# alb32r003x register map
Vendor: ALB; Series: ALB RT SoC
CPU: ALB XF, little endian
Registers are 32-bit, access not given, reset 0x0 unless marked. A register's access mark holds for its fields unless they carry their own. Offsets are from the block's base; [hi:lo] are bit positions; {n}, {i} and the like mark numbered series.

## DMA1_CTL_STA
Base 0x230022C0
Same registers: DMA2_CTL_STA 0x230032C0
0x00 RawTfr_L
  [7:0] RAW — Raw Status for IntTfr Interrupt
0x04 RawTfr_H
0x08 RawBlock_L
  [7:0] RAW — Raw Status for IntBlock Interrupt
0x0C RawBlock_H
0x10 RawSrcTran_L
  [7:0] RAW — Raw Status for IntSrcTran Interrupt
0x14 RawSrcTran_H
0x18 RawDstTran_L
  [7:0] RAW — Raw Status for IntDstTran Interrupt
0x1C RawDstTran_H
0x20 RawErr_L
  [7:0] RAW — Raw Status for IntErr Interrupt
0x24 RawErr_H
0x28 StatusTfr_L
  [7:0] STATUS — Status for IntTfr Interrupt
0x2C StatusTfr_H
0x30 StatusBlock_L
  [7:0] STATUS — Status for IntBlock Interrupt
0x34 StatusBlock_H
0x38 StatusSrcTran_L
  [7:0] STATUS — Status for IntSrcTran Interrupt
0x3C StatusSrcTran_H
0x40 StatusDstTran_L
  [7:0] STATUS — Status for IntDstTran Interrupt
0x44 StatusDstTran_H
0x48 StatusErr_L
  [7:0] STATUS — Status for IntErr Interrupt
0x4C StatusErr_H
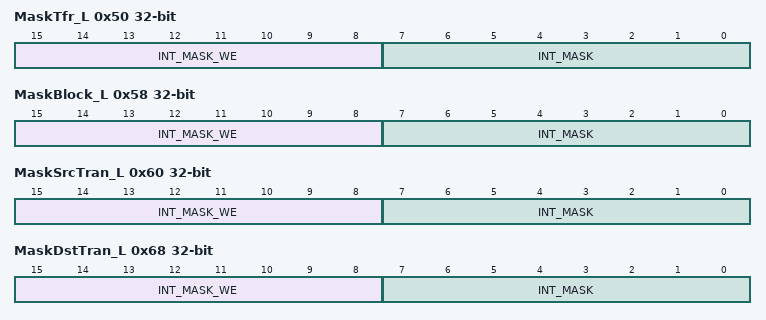
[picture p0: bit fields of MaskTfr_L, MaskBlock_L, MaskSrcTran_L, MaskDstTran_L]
0x50 MaskTfr_L
  [15:8] INT_MASK_WE — Interrupt Mask Write Enable
  [7:0] INT_MASK — Mask for IntTfr Interrupt
0x54 MaskTfr_H
0x58 MaskBlock_L
  [15:8] INT_MASK_WE — Interrupt Mask Write Enable
  [7:0] INT_MASK — Mask for IntBlock Interrupt
0x5C MaskBlock_H
0x60 MaskSrcTran_L
  [15:8] INT_MASK_WE — Interrupt Mask Write Enable
  [7:0] INT_MASK — Mask for IntSrcTran Interrupt
0x64 MaskSrcTran_H
0x68 MaskDstTran_L
  [15:8] INT_MASK_WE — Interrupt Mask Write Enable
  [7:0] INT_MASK — Mask for IntDstTran Interrupt
0x6C MaskDstTran_H
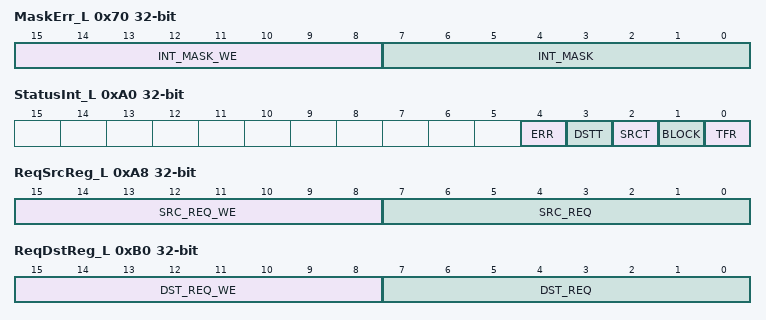
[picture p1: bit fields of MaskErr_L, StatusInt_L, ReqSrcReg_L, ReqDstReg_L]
0x70 MaskErr_L
  [15:8] INT_MASK_WE — Interrupt Mask Write Enable
  [7:0] INT_MASK — Mask for IntErr Interrupt
0x74 MaskErr_H
0x78 ClearTfr_L
  [7:0] CLEAR — Clear for IntTfr Interrupt
0x7C ClearTfr_H
0x80 ClearBlock_L
  [7:0] CLEAR — Clear for IntBlock Interrupt
0x84 ClearBlock_H
0x88 ClearSrcTran_L
  [7:0] CLEAR — Clear for IntSrcTran Interrupt
0x8C ClearSrcTran_H
0x90 ClearDstTran_L
  [7:0] CLEAR — Clear for IntDstTran Interrupt
0x94 ClearDstTran_H
0x98 ClearErr_L
  [7:0] CLEAR — Clear for IntErr Interrupt
0x9C ClearErr_H
0xA0 StatusInt_L
  [4] ERR — OR of the contents of StatusErr
  [3] DSTT — OR of the contents of StatusDstTran
  [2] SRCT — OR of the contents of StatusSrcTran
  [1] BLOCK — OR of the contents of StatusBlock register
  [0] TFR — OR of the contents of StatusTfr register
0xA4 StatusInt_H
0xA8 ReqSrcReg_L
  [15:8] SRC_REQ_WE — Source Software Transaction Request write enable
  [7:0] SRC_REQ — Source Software Transaction Request
0xAC ReqSrcReg_H
0xB0 ReqDstReg_L
  [15:8] DST_REQ_WE — Destination Software Transaction Request write enable
  [7:0] DST_REQ — Destination Software Transaction Request
0xB4 ReqDstReg_H
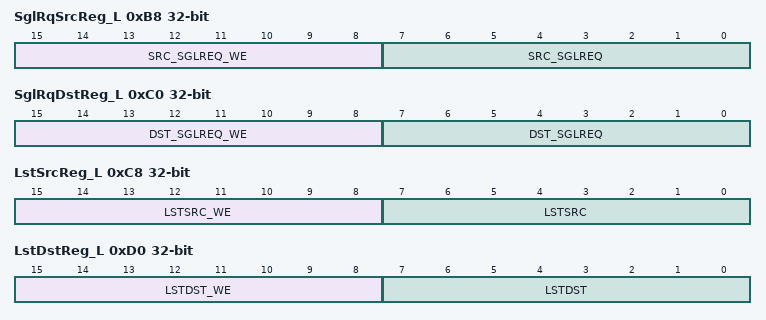
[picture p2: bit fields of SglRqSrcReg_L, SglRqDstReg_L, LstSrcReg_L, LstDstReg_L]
0xB8 SglRqSrcReg_L
  [15:8] SRC_SGLREQ_WE — Source Single Transaction Request write enable
  [7:0] SRC_SGLREQ — Source Single Transaction Request
0xBC SglRqSrcReg_H
0xC0 SglRqDstReg_L
  [15:8] DST_SGLREQ_WE — Destination Single Transaction Request write enable
  [7:0] DST_SGLREQ — Destination Single Transaction Request
0xC4 SglRqDstReg_H
0xC8 LstSrcReg_L
  [15:8] LSTSRC_WE — Source Last Transaction Request write enable
  [7:0] LSTSRC — Source Last Transaction Request register
0xCC LstSrcReg_H
0xD0 LstDstReg_L
  [15:8] LSTDST_WE — Source Last Transaction Request write enable
  [7:0] LSTDST — Destination Last Transaction Request
0xD4 LstDstReg_H
0xD8 DmaCfgReg_L
  [0] DMA_EN — DW_ahb_dmac Enable bit.
0xDC DmaCfgReg_H
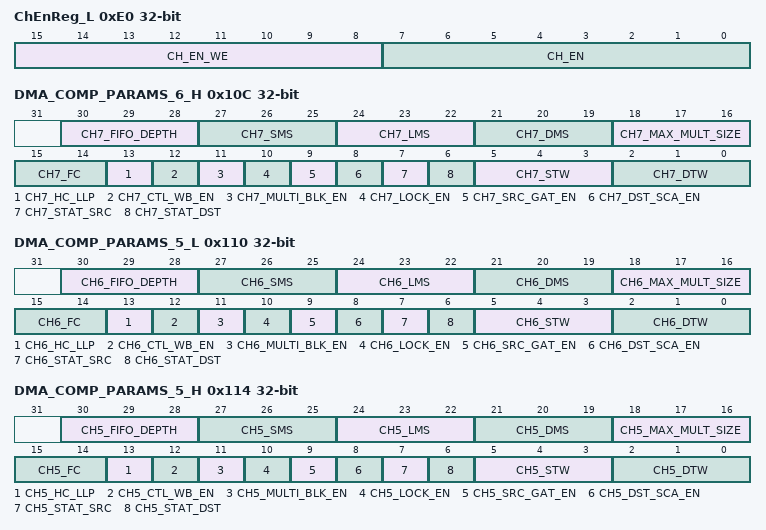
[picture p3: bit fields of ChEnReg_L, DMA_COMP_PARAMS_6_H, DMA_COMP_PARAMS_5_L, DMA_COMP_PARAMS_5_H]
0xE0 ChEnReg_L
  [15:8] CH_EN_WE — Channel enable register
  [7:0] CH_EN — Channel Enable. The ChEnReg.CH_EN bit is automatically
0xE4 ChEnReg_H
0xE8 DmaIdReg_L
  [31:0] DMA_ID — Hardcoded DW_ahb_dmac peripheral ID.
0xEC DmaIdReg_H
0xF0 DmaTestReg_L
  [0] TEST_SLV_IF — DMA Test register
0xF4 DmaTestReg_H
0xF8 DmaLpTimeoutReg_L
  [31:0] DMA_LP_TIMEOUT — This field holds timeout value of low power counter register.
0xFC DmaLpTimeoutReg_H
0x108 DMA_COMP_PARAMS_6_L
0x10C DMA_COMP_PARAMS_6_H
  [30:28] CH7_FIFO_DEPTH — Channel 7 FIFO depth
  [27:25] CH7_SMS — Channel 7 Source Master
  [24:22] CH7_LMS — Channel 7 LLP Master
  [21:19] CH7_DMS — Channel 7 Destination Master
  [18:16] CH7_MAX_MULT_SIZE — Channel 7 Maximum MULT Size
  [15:14] CH7_FC — Channel 7 Flow Controller
  [13] CH7_HC_LLP — Channel 7 Hardcode LLP
  [12] CH7_CTL_WB_EN — Channel 7 Control Writeback Enable
  [11] CH7_MULTI_BLK_EN — Channel 7 MultiBlock Enable
  [10] CH7_LOCK_EN — Channel 7 locking Enable
  [9] CH7_SRC_GAT_EN — Channel 7 Source gather Enable
  [8] CH7_DST_SCA_EN — Channel 7 Destination scatter Enable
  [7] CH7_STAT_SRC — Channel 7 Status Source
  [6] CH7_STAT_DST — Channel 7 Status Destination
  [5:3] CH7_STW — Channel 7 Source Transfer Width
  [2:0] CH7_DTW — Channel 7 Destination Transfer Width
0x110 DMA_COMP_PARAMS_5_L
  [30:28] CH6_FIFO_DEPTH — Channel 6 FIFO depth
  [27:25] CH6_SMS — Channel 6 Source Master
  [24:22] CH6_LMS — Channel 6 LLP Master
  [21:19] CH6_DMS — Channel 6 Destination Master
  [18:16] CH6_MAX_MULT_SIZE — Channel 6 Maximum MULT Size
  [15:14] CH6_FC — Channel 6 Flow Controller
  [13] CH6_HC_LLP — Channel 6 Hardcode LLP
  [12] CH6_CTL_WB_EN — Channel 6 Control Writeback Enable
  [11] CH6_MULTI_BLK_EN — Channel 6 MultiBlock Enable
  [10] CH6_LOCK_EN — Channel 6 locking Enable
  [9] CH6_SRC_GAT_EN — Channel 6 Source gather Enable
  [8] CH6_DST_SCA_EN — Channel 6 Destination scatter Enable
  [7] CH6_STAT_SRC — Channel 6 Status Source
  [6] CH6_STAT_DST — Channel 6 Status Destination
  [5:3] CH6_STW — Channel 6 Source Transfer Width
  [2:0] CH6_DTW — Channel 6 Destination Transfer Width
0x114 DMA_COMP_PARAMS_5_H
  [30:28] CH5_FIFO_DEPTH — Channel 5 FIFO depth
  [27:25] CH5_SMS — Channel 5 Source Master
  [24:22] CH5_LMS — Channel 5 LLP Master
  [21:19] CH5_DMS — Channel 5 Destination Master
  [18:16] CH5_MAX_MULT_SIZE — Channel 5 Maximum MULT Size
  [15:14] CH5_FC — Channel 5 Flow Controller
  [13] CH5_HC_LLP — Channel 5 Hardcode LLP
  [12] CH5_CTL_WB_EN — Channel 5 Control Writeback Enable
  [11] CH5_MULTI_BLK_EN — Channel 5 MultiBlock Enable
  [10] CH5_LOCK_EN — Channel 5 locking Enable
  [9] CH5_SRC_GAT_EN — Channel 5 Source gather Enable
  [8] CH5_DST_SCA_EN — Channel 5 Destination scatter Enable
  [7] CH5_STAT_SRC — Channel 5 Status Source
  [6] CH5_STAT_DST — Channel 5 Status Destination
  [5:3] CH5_STW — Channel 5 Source Transfer Width
  [2:0] CH5_DTW — Channel 5 Destination Transfer Width
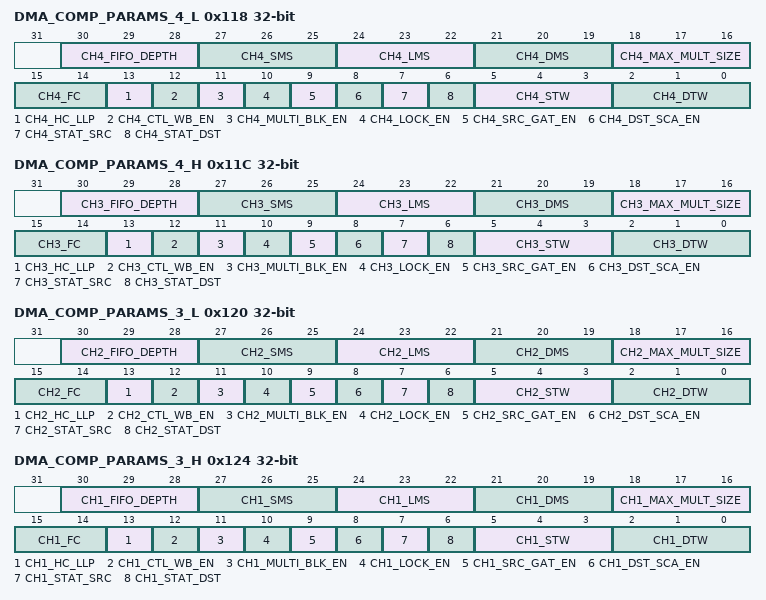
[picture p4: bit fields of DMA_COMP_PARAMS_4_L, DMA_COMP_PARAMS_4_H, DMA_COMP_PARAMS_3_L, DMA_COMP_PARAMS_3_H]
0x118 DMA_COMP_PARAMS_4_L
  [30:28] CH4_FIFO_DEPTH — Channel 4 FIFO depth
  [27:25] CH4_SMS — Channel 4 Source Master
  [24:22] CH4_LMS — Channel 4 LLP Master
  [21:19] CH4_DMS — Channel 4 Destination Master
  [18:16] CH4_MAX_MULT_SIZE — Channel 4 Maximum MULT Size
  [15:14] CH4_FC — Channel 4 Flow Controller
  [13] CH4_HC_LLP — Channel 4 Hardcode LLP
  [12] CH4_CTL_WB_EN — Channel 4 Control Writeback Enable
  [11] CH4_MULTI_BLK_EN — Channel 4 MultiBlock Enable
  [10] CH4_LOCK_EN — Channel 4 locking Enable
  [9] CH4_SRC_GAT_EN — Channel 4 Source gather Enable
  [8] CH4_DST_SCA_EN — Channel 4 Destination scatter Enable
  [7] CH4_STAT_SRC — Channel 4 Status Source
  [6] CH4_STAT_DST — Channel 4 Status Destination
  [5:3] CH4_STW — Channel 4 Source Transfer Width
  [2:0] CH4_DTW — Channel 4 Destination Transfer Width
0x11C DMA_COMP_PARAMS_4_H
  [30:28] CH3_FIFO_DEPTH — Channel 3 FIFO depth
  [27:25] CH3_SMS — Channel 3 Source Master
  [24:22] CH3_LMS — Channel 3 LLP Master
  [21:19] CH3_DMS — Channel 3 Destination Master
  [18:16] CH3_MAX_MULT_SIZE — Channel 3 Maximum MULT Size
  [15:14] CH3_FC — Channel 3 Flow Controller
  [13] CH3_HC_LLP — Channel 3 Hardcode LLP
  [12] CH3_CTL_WB_EN — Channel 3 Control Writeback Enable
  [11] CH3_MULTI_BLK_EN — Channel 3 MultiBlock Enable
  [10] CH3_LOCK_EN — Channel 3 locking Enable
  [9] CH3_SRC_GAT_EN — Channel 3 Source gather Enable
  [8] CH3_DST_SCA_EN — Channel 3 Destination scatter Enable
  [7] CH3_STAT_SRC — Channel 3 Status Source
  [6] CH3_STAT_DST — Channel 3 Status Destination
  [5:3] CH3_STW — Channel 3 Source Transfer Width
  [2:0] CH3_DTW — Channel 3 Destination Transfer Width
0x120 DMA_COMP_PARAMS_3_L
  [30:28] CH2_FIFO_DEPTH — Channel 2 FIFO depth
  [27:25] CH2_SMS — Channel 2 Source Master
  [24:22] CH2_LMS — Channel 2 LLP Master
  [21:19] CH2_DMS — Channel 2 Destination Master
  [18:16] CH2_MAX_MULT_SIZE — Channel 2 Maximum MULT Size
  [15:14] CH2_FC — Channel 2 Flow Controller
  [13] CH2_HC_LLP — Channel 2 Hardcode LLP
  [12] CH2_CTL_WB_EN — Channel 2 Control Writeback Enable
  [11] CH2_MULTI_BLK_EN — Channel 2 MultiBlock Enable
  [10] CH2_LOCK_EN — Channel 2 locking Enable
  [9] CH2_SRC_GAT_EN — Channel 2 Source gather Enable
  [8] CH2_DST_SCA_EN — Channel 2 Destination scatter Enable
  [7] CH2_STAT_SRC — Channel 2 Status Source
  [6] CH2_STAT_DST — Channel 2 Status Destination
  [5:3] CH2_STW — Channel 2 Source Transfer Width
  [2:0] CH2_DTW — Channel 2 Destination Transfer Width
0x124 DMA_COMP_PARAMS_3_H
  [30:28] CH1_FIFO_DEPTH — Channel 1 FIFO depth
  [27:25] CH1_SMS — Channel 1 Source Master
  [24:22] CH1_LMS — Channel 1 LLP Master
  [21:19] CH1_DMS — Channel 1 Destination Master
  [18:16] CH1_MAX_MULT_SIZE — Channel 1 Maximum MULT Size
  [15:14] CH1_FC — Channel 1 Flow Controller
  [13] CH1_HC_LLP — Channel 1 Hardcode LLP
  [12] CH1_CTL_WB_EN — Channel 1 Control Writeback Enable
  [11] CH1_MULTI_BLK_EN — Channel 1 MultiBlock Enable
  [10] CH1_LOCK_EN — Channel 1 locking Enable
  [9] CH1_SRC_GAT_EN — Channel 1 Source gather Enable
  [8] CH1_DST_SCA_EN — Channel 1 Destination scatter Enable
  [7] CH1_STAT_SRC — Channel 1 Status Source
  [6] CH1_STAT_DST — Channel 1 Status Destination
  [5:3] CH1_STW — Channel 1 Source Transfer Width
  [2:0] CH1_DTW — Channel 1 Destination Transfer Width
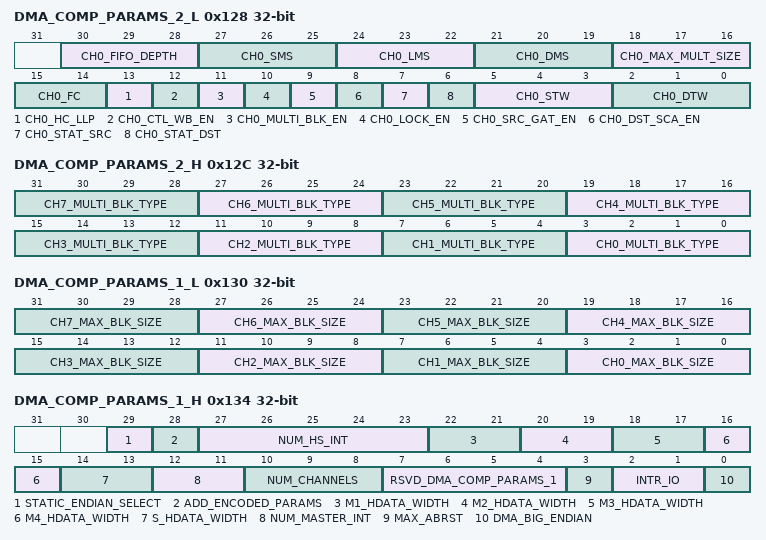
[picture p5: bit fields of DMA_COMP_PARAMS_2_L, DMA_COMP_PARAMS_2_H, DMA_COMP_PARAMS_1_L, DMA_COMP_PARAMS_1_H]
0x128 DMA_COMP_PARAMS_2_L
  [30:28] CH0_FIFO_DEPTH — Channel 0 FIFO depth
  [27:25] CH0_SMS — Channel 0 Source Master
  [24:22] CH0_LMS — Channel 0 LLP Master
  [21:19] CH0_DMS — Channel 0 Destination Master
  [18:16] CH0_MAX_MULT_SIZE — Channel 0 Maximum MULT Size
  [15:14] CH0_FC — Channel 0 Flow Controller
  [13] CH0_HC_LLP — Channel 0 Hardcode LLP
  [12] CH0_CTL_WB_EN — Channel 0 Control Writeback Enable
  [11] CH0_MULTI_BLK_EN — Channel 0 MultiBlock Enable
  [10] CH0_LOCK_EN — Channel 0 locking Enable
  [9] CH0_SRC_GAT_EN — Channel 0 Source gather Enable
  [8] CH0_DST_SCA_EN — Channel 0 Destination scatter Enable
  [7] CH0_STAT_SRC — Channel 0 Status Source
  [6] CH0_STAT_DST — Channel 0 Status Destination
  [5:3] CH0_STW — Channel 0 Source Transfer Width
  [2:0] CH0_DTW — Channel 0 Destination Transfer Width
0x12C DMA_COMP_PARAMS_2_H
  [4n+3:4n] CH{n}_MULTI_BLK_TYPE (n=0..7) — Channel {n} MultiBlock Type
0x130 DMA_COMP_PARAMS_1_L
  [4n+3:4n] CH{n}_MAX_BLK_SIZE (n=0..7) — Channel {n} Maximum Block Size
0x134 DMA_COMP_PARAMS_1_H
  [29] STATIC_ENDIAN_SELECT
  [28] ADD_ENCODED_PARAMS — Add Encoded Parameter
  [27:23] NUM_HS_INT — Number of handshaking interfaces
  [24-2n:23-2n] M{n}_HDATA_WIDTH (n=1..4) — Master{n} Interface Data Bus Width
  [14:13] S_HDATA_WIDTH — Slave Interface Data Bus Width
  [12:11] NUM_MASTER_INT — Number of MASTER Interface
  [10:8] NUM_CHANNELS — Number of DMA Channels
  [7:4] RSVD_DMA_COMP_PARAMS_1 — Reserved field read only
  [3] MAX_ABRST — Maximum AMBA
  [2:1] INTR_IO — Interrupt IO
  [0] DMA_BIG_ENDIAN
0x138 DmaCompsID_L
  [31:0] DMA_COMP_TYPE — DMA Component Type
0x13C DmaCompsID_H
  [31:0] DMA_COMP_VERSION — DMA Component Version
